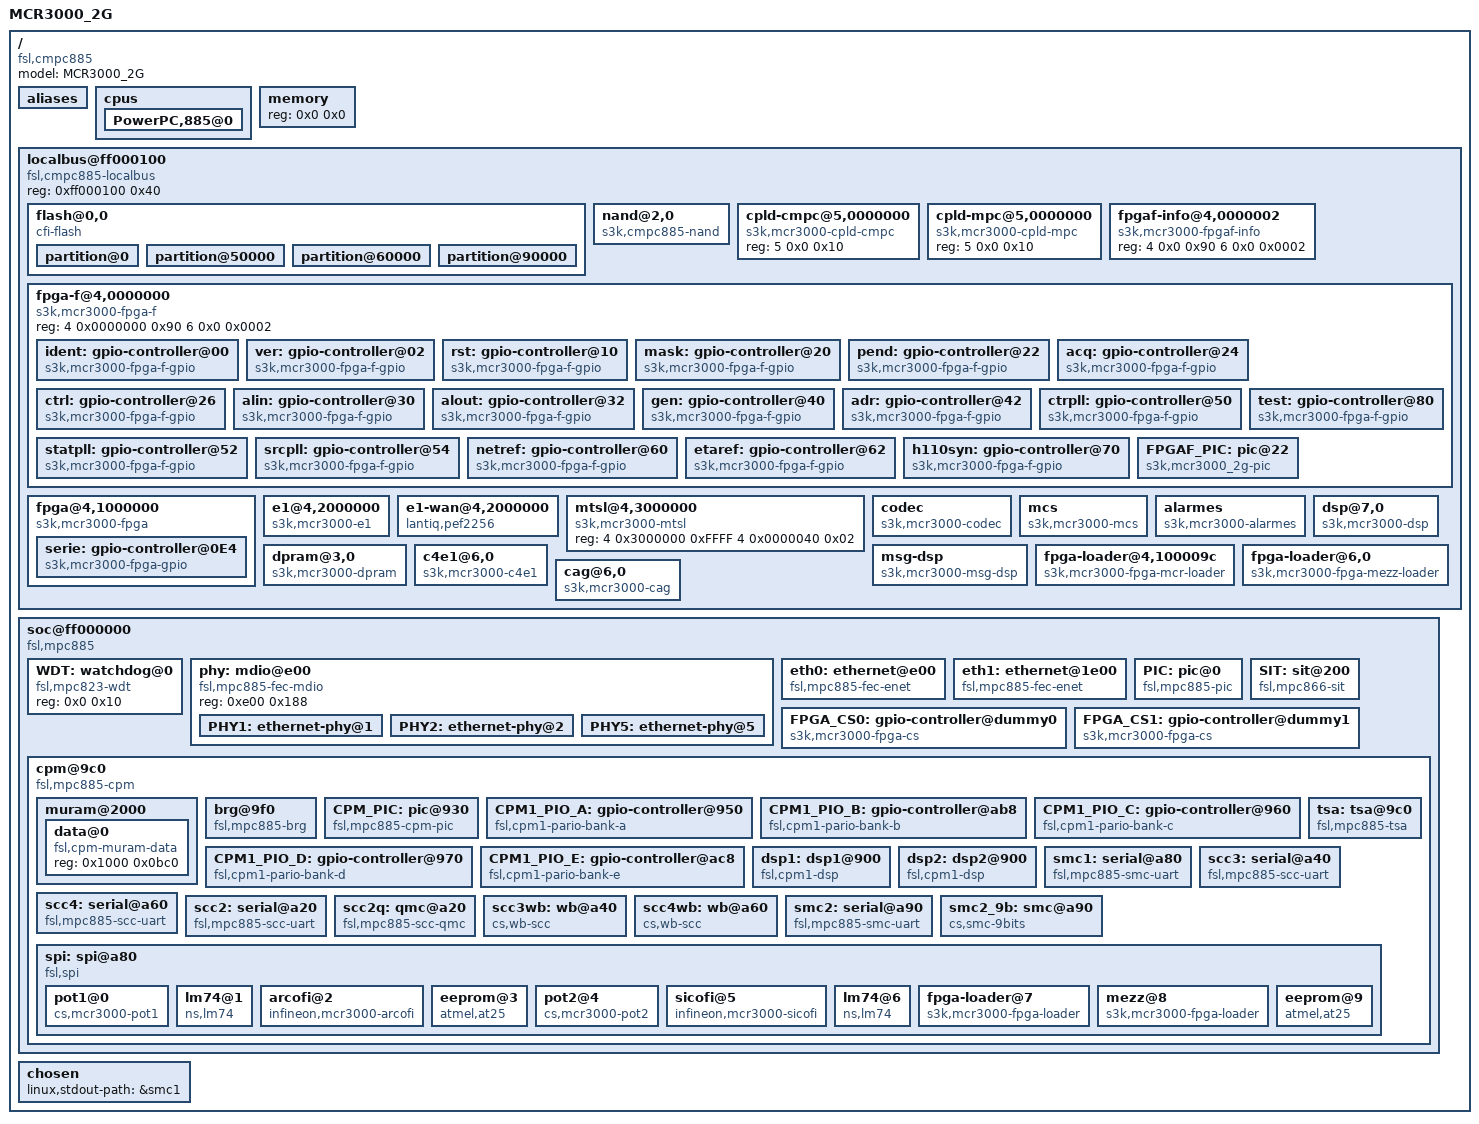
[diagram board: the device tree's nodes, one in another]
/*
 * MCR3000_2G Device Tree Source
 *
 * Copyright 2010 CSSI, Inc
 */

/dts-v1/;

/ {
	model = "MCR3000_2G";
	compatible = "fsl,cmpc885", "fsl,mod885", "fsl,base";
	#address-cells = <1>;
	#size-cells = <1>;

	aliases {
		ethernet0 = &eth0;
		ethernet1 = &eth1;
		mdio = &phy;
		serial0 = &smc1;
	};

	cpus {
		#address-cells = <1>;
		#size-cells = <0>;

		PowerPC,885@0 {
			device_type = "cpu";
			reg = <0x0>;
			d-cache-line-size = <16>;	// 16 bytes
			i-cache-line-size = <16>;	// 16 bytes
			d-cache-size = <8192>;
			i-cache-size = <8192>;
			timebase-frequency = <0>;
			bus-frequency = <0>;
			clock-frequency = <0>;
			interrupts = <15 2>;		// decrementer interrupt
			interrupt-parent = <&PIC>;
		};
	};

	memory {
		device_type = "memory";
		reg = <0x0 0x0>;			// defined by U-BOOT
	};

	localbus@ff000100 {
		compatible = "fsl,cmpc885-localbus", "fsl,pq1-localbus";
		#address-cells = <2>;
		#size-cells = <1>;
		reg = <0xff000100 0x40>;		// ORx and BRx register

		ranges = <0 0x0 0x40000000 0x00400000 // Boot Flash
			  1 0x0 0x00000000 0x08000000 // SDRAM
			  2 0x0 0xc0000000 0x00008000 // Nand Flash
			  3 0x0 0xe0000000 0x00010000 // DPRAM
			  4 0x0 0xd0000000 0x10000000 // Periphs
			  5 0x0 0xc8000000 0x00008000 // CPLD
			  6 0x0 0x80000000 0x00008000 // mezzanine
			  7 0x0 0xf0000000 0x00008000>; // DSP

		flash@0,0 {
			#address-cells = <1>;
			#size-cells = <1>;
			compatible = "cfi-flash";
			reg = <0x0 0x00000000 0x400000>;
			bank-width = <2>;
			device-width = <2>;
			partition@0 {
				label = "boot";
				reg = <0x0 0x50000>;
			};
			partition@50000 {
				label = "env";
				reg = <0x50000 0x10000>;
			};
			partition@60000 {
				label = "blob";
				reg = <0x60000 0x30000>;
			};
			partition@90000 {
				label = "kernel";
				reg = <0x90000 0x370000>;
			};
		};

		nand@2,0 {
			compatible = "s3k,cmpc885-nand";
			reg = <2 0x0 0x01>;
			#address-cells = <1>;
			#size-cells = <1>;
			gpios = <&CPM1_PIO_D 12 1 	// CLE
				 &CPM1_PIO_D 13 1	// ALE
				 &CPM1_PIO_D 15 1>;	// NCE
		};

		cpld-cmpc@5,0000000 { // Driver KNL
			#address-cells = <1>;
			#size-cells = <1>;
			compatible = "s3k,mcr3000-cpld-cmpc";
			reg = <5 0x0 0x10>;
		};
		
		cpld-mpc@5,0000000 { // Driver LDB (deviendra obsolete)
			#address-cells = <1>;
			#size-cells = <1>;
			compatible = "s3k,mcr3000-cpld-mpc";
			reg = <5 0x0 0x10>;
		};
		
		fpgaf-info@4,0000002 { // Driver KNL
			#address-cells = <1>;
			#size-cells = <1>;
			compatible = "s3k,mcr3000-fpgaf-info";
			reg = <4 0x0 0x90 6 0x0 0x0002>;	// Mappage registres FPGAF ; Ident carte Mezzanine
		};

		fpga-f@4,0000000 { // Driver LDB (deviendra peut etre obsolete)
			#address-cells = <1>;
			#size-cells = <1>;
			compatible = "s3k,mcr3000-fpga-f";
			reg = <4 0x0000000 0x90 6 0x0 0x0002>;
			ranges = <0 4 0x0000000 0x90>;
			ident: gpio-controller@00 {
				#gpio-cells = <2>;
				compatible = "s3k,mcr3000-fpga-f-gpio";
				reg = <0x00 2>;
				gpio-controller;
			};
			ver: gpio-controller@02 {
				#gpio-cells = <2>;
				compatible = "s3k,mcr3000-fpga-f-gpio";
				reg = <0x02 2>;
				gpio-controller;
			};
			rst: gpio-controller@10 {
				#gpio-cells = <2>;
				compatible = "s3k,mcr3000-fpga-f-gpio";
				reg = <0x10 2>;
				gpio-controller;
			};
			mask: gpio-controller@20 {
				#gpio-cells = <2>;
				compatible = "s3k,mcr3000-fpga-f-gpio";
				reg = <0x20 2>;
				gpio-controller;
			};
			pend: gpio-controller@22 {
				#gpio-cells = <2>;
				compatible = "s3k,mcr3000-fpga-f-gpio";
				reg = <0x22 2>;
				gpio-controller;
			};
			acq: gpio-controller@24 {
				#gpio-cells = <2>;
				compatible = "s3k,mcr3000-fpga-f-gpio";
				reg = <0x24 2>;
				gpio-controller;
			};
			ctrl: gpio-controller@26 {
				#gpio-cells = <2>;
				compatible = "s3k,mcr3000-fpga-f-gpio";
				reg = <0x26 2>;
				gpio-controller;
			};
			alin: gpio-controller@30 {
				#gpio-cells = <2>;
				compatible = "s3k,mcr3000-fpga-f-gpio";
				reg = <0x30 2>;
				interrupts = <255 255 255 255 255 255 255 255 8 9 10 11 12 13 14 15>;
				interrupt-parent = <&FPGAF_PIC>;
				gpio-controller;
			};
			alout: gpio-controller@32 {
				#gpio-cells = <2>;
				compatible = "s3k,mcr3000-fpga-f-gpio";
				reg = <0x32 2>;
				gpio-controller;
			};
			gen: gpio-controller@40 {
				#gpio-cells = <2>;
				compatible = "s3k,mcr3000-fpga-f-gpio";
				reg = <0x40 2>;
				gpio-controller;
			};
			adr: gpio-controller@42 {
				#gpio-cells = <2>;
				compatible = "s3k,mcr3000-fpga-f-gpio";
				reg = <0x42 2>;
				gpio-controller;
			};
			ctrpll: gpio-controller@50 {
				#gpio-cells = <2>;
				compatible = "s3k,mcr3000-fpga-f-gpio";
				reg = <0x50 2>;
				gpio-controller;
			};
			statpll: gpio-controller@52 {
				#gpio-cells = <2>;
				compatible = "s3k,mcr3000-fpga-f-gpio";
				reg = <0x52 2>;
				gpio-controller;
			};
			srcpll: gpio-controller@54 {
				#gpio-cells = <2>;
				compatible = "s3k,mcr3000-fpga-f-gpio";
				reg = <0x54 2>;
				gpio-controller;
			};
			netref: gpio-controller@60 {
				#gpio-cells = <2>;
				compatible = "s3k,mcr3000-fpga-f-gpio";
				reg = <0x60 2>;
				gpio-controller;
			};
			etaref: gpio-controller@62 {
				#gpio-cells = <2>;
				compatible = "s3k,mcr3000-fpga-f-gpio";
				reg = <0x62 2>;
				interrupts = <255 255 255 255 255 255 255 255 255 255 2 4 3 5 6 7>;
				interrupt-parent = <&FPGAF_PIC>;
				gpio-controller;
			};
			h110syn: gpio-controller@70 {
				#gpio-cells = <2>;
				compatible = "s3k,mcr3000-fpga-f-gpio";
				reg = <0x70 2>;
				gpio-controller;
			};
			test: gpio-controller@80 {
				#gpio-cells = <2>;
				compatible = "s3k,mcr3000-fpga-f-gpio";
				reg = <0x80 2>;
				gpio-controller;
			};
			FPGAF_PIC: pic@22 {
				interrupt-controller;
				#address-cells = <0>;
				#interrupt-cells = <1>;
				interrupts = <14 1>;
				interrupt-parent = <&PIC>;
				reg = <0x0 0x90>;	// Mappage registres FPGAF
				compatible = "s3k,mcr3000_2g-pic";
			};
		};
		
		fpga@4,1000000 {
			#address-cells = <1>;
			#size-cells = <1>;
			compatible = "s3k,mcr3000-fpga";
			reg = <4 0x1000000 0x0200 6 0x0 0x0002 4 0x60 0x02 4 0x10000E8 0x02>;
			/* registres FPGA - Registre ident MEZZ (1G) - Registre NetRef FPGAF - Registre BRG5 FPGA */
			ranges = <0 4 0x1000000 0x0200>;
			liens = "SCC3", "SCC4", "SCC2", "SMC2";
//			interrupts = <0>;
//			interrupt-parent = <&FPGA_PIC>;
			interrupts = <6 1>;
			interrupt-parent = <&PIC>;
			serie: gpio-controller@0E4 {
				#gpio-cells = <2>;
				compatible = "s3k,mcr3000-fpga-gpio";
				reg = <0x0E4 2>;
				gpio-controller;
			};
//			FPGA_PIC: pic@1000000 {
//				interrupt-controller;
//				#address-cells = <0>;
//				#interrupt-cells = <1>;
//				interrupts = <6 1>;
//				interrupt-parent = <&PIC>;
//				reg = <0x0 0x0200>;	/* Mappage registres FPGA */
//				compatible = "s3k,mcr3000-fpga-pic";
//			};
		};
		
//		uart-fpga@4,1000000 {
//			#address-cells = <1>;
//			#size-cells = <1>;
//			compatible = "ns16550a";
//			/* adresse uart 16550a et taille utile */
//			reg = <4 0x1000100 0x100>;
//			reg-shift = <1>;
//			fifo-size = <32>;
//			clock = "fpga";
//			interrupts = <1>;
//			interrupt-parent = <&FPGA_PIC>;
//		};

		e1@4,2000000 {
			#address-cells = <1>;
			#size-cells = <1>;
			compatible = "s3k,mcr3000-e1";
			reg = <4 0x2000000 0xFF>;
			interrupts = <8 1>;
			interrupt-parent = <&PIC>;
		};
		
		e1-wan@4,2000000 {
			#address-cells = <1>;
			#size-cells = <1>;
			compatible = "lantiq,pef2256";
			reg = <4 0x2000000 0xFF>;
			interrupts = <8 1>;
			interrupt-parent = <&PIC>;
		};
		
		mtsl@4,3000000 {
			#address-cells = <1>;
			#size-cells = <1>;
			compatible = "s3k,mcr3000-mtsl";
			reg = <4 0x3000000 0xFFFF 4 0x0000040 0x02>;
		};

		codec {
			compatible = "s3k,mcr3000-codec";
		};

		mcs {
			compatible = "s3k,mcr3000-mcs";
		};

		alarmes {
			compatible = "s3k,mcr3000-alarmes";
			gpios = <&alin 13 1 	// ACQ_ALRM
				&alout 15 1	// ALRM_MAJ
				&alout 14 1>;	// ALRM_MIN
		};
		
		dpram@3,0 {
			#address-cells = <1>;
			#size-cells = <1>;
			compatible = "s3k,mcr3000-dpram";
			reg = <3 0x0 0x10000>;
			interrupts = <4 1>;
			interrupt-parent = <&PIC>;
		};

		dsp@7,0 {
			#address-cells = <1>;
			#size-cells = <1>;
			compatible = "s3k,mcr3000-dsp";
			reg = <7 0x0 0x0008>;
			interrupts = <0 1>;
			interrupt-parent = <&FPGAF_PIC>;
		};

		msg-dsp {
			#address-cells = <1>;
			#size-cells = <1>;
			compatible = "s3k,mcr3000-msg-dsp";
			reg = <3 0x0 0x300>;
			interrupts = <0 1>;
			interrupt-parent = <&FPGAF_PIC>;
		};

		fpga-loader@4,100009c {
			#address-cells = <1>;
			#size-cells = <1>;
			compatible = "s3k,mcr3000-fpga-mcr-loader";
			reg = <4 0x100009c 2>;			// Version FPGA
			gpios = <&FPGA_CS0 1 1			// INITFPGA
				 &CPM1_PIO_E 23 1		// DONEFPGA
				 &rst 13 1 >;			// RST_FPGA
		};
		c4e1@6,0 {
			#address-cells = <1>;
			#size-cells = <1>;
			compatible = "s3k,mcr3000-c4e1";
			reg = <6 0x100 0x00FF 6 0x200 0x00FF 6 0x300 0x00FF 6 0x400 0x00FF 6 0x500 0x00FF>;
			interrupts = <12 1>;
			interrupt-parent = <&PIC>;
		};

		fpga-loader@6,0 {
			#address-cells = <1>;
			#size-cells = <1>;
			compatible = "s3k,mcr3000-fpga-mezz-loader";
			reg = <6 0x500 2>; 		// Version FPGA Mezz
			gpios = <&FPGA_CS1 1 1		// INIT Mezz
				&CPM1_PIO_B 17 1	// DONE Mezz
				&rst 9 1 >;		// RST Mezz
		};

		cag@6,0 {
			#address-cells = <1>;
			#size-cells = <1>;
			compatible = "s3k,mcr3000-cag";
			reg = <6 0x0 0x0020>;
			interrupts = <12 1>;
			interrupt-parent = <&PIC>;
		};
	};

	soc@ff000000 {
		compatible = "fsl,mpc885", "fsl,pq1-soc";
		#address-cells = <1>;
		#size-cells = <1>;
		device_type = "soc";
		ranges = <0x0 0xff000000 0x28000>;
		bus-frequency = <0>;
		clock-frequency = <0>;

		WDT: watchdog@0 {
			compatible = "fsl,mpc823-wdt";
			reg = <0x0 0x10>;
		};

		phy: mdio@e00 {
			compatible = "fsl,mpc885-fec-mdio", "fsl,pq1-fec-mdio";
			reg = <0xe00 0x188>;
			#address-cells = <1>;
			#size-cells = <0>;

			PHY1: ethernet-phy@1 {
				interrupts = <2 1>;
				interrupt-parent = <&PIC>;
				reg = <0x1>;
				device_type = "ethernet-phy";
			};

			PHY2: ethernet-phy@2 {
				interrupts = <2 1>;
				interrupt-parent = <&PIC>;
				reg = <0x2>;
				device_type = "ethernet-phy";
			};

			PHY5: ethernet-phy@5 {
				interrupts = <2 1>;
				interrupt-parent = <&PIC>;
				reg = <0x5>;
				device_type = "ethernet-phy";
			};
		};

		eth0: ethernet@e00 {
			device_type = "network";
			compatible = "fsl,mpc885-fec-enet", "fsl,pq1-fec-enet";
			reg = <0xe00 0x188>;
			local-mac-address = [ 00 00 00 00 00 00 ];
			interrupts = <5 1>;
			interrupt-parent = <&PIC>;
			phy-handle = <&PHY1 &PHY5>;
			linux,network-index = <0>;
			use-PHY5;
			gpios = <&rst 15 1>;		// Reset Eth1
			PHY-disable = "isolate";
		};

		eth1: ethernet@1e00 {
			device_type = "network";
			compatible = "fsl,mpc885-fec-enet", "fsl,pq1-fec-enet";
			reg = <0x1e00 0x188>;
			local-mac-address = [ 00 00 00 00 00 00 ];
			interrupts = <7 1>;
			interrupt-parent = <&PIC>;
			phy-handle = <&PHY2>;
			linux,network-index = <1>;
		};

		PIC: pic@0 {
			interrupt-controller;
			#interrupt-cells = <2>;
			reg = <0x0 0x24>;
			compatible = "fsl,mpc885-pic", "fsl,pq1-pic";
		};

		SIT: sit@200 {
			compatible = "fsl,mpc866-sit", "fsl,pq1-sit";
			reg = <0x200 0x80>;
			interrupts = <11 1>;
			interrupt-parent = <&PIC>;
		};

		FPGA_CS0: gpio-controller@dummy0 {
			#gpio-cells = <2>;
			compatible = "s3k,mcr3000-fpga-cs";
			gpio-controller;
			reg = <0x0 0x1>;	// necessaire mais non utilise
			gpios = <&CPM1_PIO_E 18 1	// PROGFPGA
				 &CPM1_PIO_D 6 1>;	// INITFPGA
		};
		FPGA_CS1: gpio-controller@dummy1 {
			#gpio-cells = <2>;
			compatible = "s3k,mcr3000-fpga-cs";
			gpio-controller;
			reg = <0x1 0x1>; /* necessaire mais non utilise */
			gpios = <&CPM1_PIO_B 16 1	// PROG
				 &CPM1_PIO_B 22 1>;	// INIT
		};

		cpm@9c0 {
			#address-cells = <1>;
			#size-cells = <1>;
			compatible = "fsl,mpc885-cpm", "fsl,cpm1";
			ranges;
			reg = <0x9c0 0x40>;
			brg-frequency = <0>;
			interrupts = <0>;	// cpm error interrupt
			interrupt-parent = <&CPM_PIC>;

			muram@2000 {
				#address-cells = <1>;
				#size-cells = <1>;
				ranges = <0x0 0x2000 0x2000>;

				/* conserver les 4 premiers Kbytes pour QMC */
				data@0 {
					compatible = "fsl,cpm-muram-data";
					reg = <0x1000 0x0bc0>;
				};
			};

			brg@9f0 {
				compatible = "fsl,mpc885-brg", "fsl,cpm1-brg", "fsl,cpm-brg";
				reg = <0x9f0 0x10>;
				clock-frequency = <0>;
			};

			CPM_PIC: pic@930 {
				interrupt-controller;
				#address-cells = <0>;
				#interrupt-cells = <1>;
				interrupts = <3 2 0 2>;
				interrupt-parent = <&PIC>;
				reg = <0x930 0x20>;
				compatible = "fsl,mpc885-cpm-pic", "fsl,cpm1-pic";
			};

			CPM1_PIO_A: gpio-controller@950 {
				#gpio-cells = <2>;
				compatible = "fsl,cpm1-pario-bank-a";
				reg = <0x950 0x10>;
				gpio-controller;
			};
		
			CPM1_PIO_B: gpio-controller@ab8 {
				#gpio-cells = <2>;
				compatible = "fsl,cpm1-pario-bank-b";
				reg = <0xab8 0x10>;
				gpio-controller;
			};
		
			CPM1_PIO_C: gpio-controller@960 {
				#gpio-cells = <2>;
				compatible = "fsl,cpm1-pario-bank-c";
				reg = <0x960 0x10>;
				interrupts = <0 0 0 0 1 2 6 9 10 11 14 15 23 24 26 31>;
				interrupt-parent = <&CPM_PIC>;
				gpio-controller;
			};
		
			CPM1_PIO_D: gpio-controller@970 {
				#gpio-cells = <2>;
				compatible = "fsl,cpm1-pario-bank-d";
				reg = <0x970 0x10>;
				gpio-controller;
			};
		
			CPM1_PIO_E: gpio-controller@ac8 {
				#gpio-cells = <2>;
				compatible = "fsl,cpm1-pario-bank-e";
				reg = <0xac8 0x18>;
				gpio-controller;
			};
			
			dsp1: dsp1@900 {
				device_type = "dsp";
				compatible = "fsl,cpm1-dsp";
				reg = <0x900 0x30 0x3ec0 0x40>;
				interrupts = <22>;
				interrupt-parent = <&CPM_PIC>;
				fsl,cpm-dsp = <1>;
				fsl,cpm-command = <0x90>;
			};

			dsp2: dsp2@900 {
				device_type = "dsp";
				compatible = "fsl,cpm1-dsp";
				reg = <0x900 0x30 0x3fc0 0x40>;
				interrupts = <22>;
				interrupt-parent = <&CPM_PIC>;
				fsl,cpm-dsp = <2>;
				fsl,cpm-command = <0xd0>;
			};

			tsa: tsa@9c0 {
				compatible = "fsl,mpc885-tsa", "fsl,cpm1-tsa";
				reg = <0x9c0 0x440 0x930 0x20>;
				/* parametres possible : none, SCC2 */
				scc_qmc_mcr = "SCC2";
				/* parametre enregistrement : TS sup 0 a 16 */
				ts_enreg = <16>;
			};

			smc1: serial@a80 {
				device_type = "serial";
				compatible = "fsl,mpc885-smc-uart", "fsl,cpm1-smc-uart";
				reg = <0xa80 0x10 0x3e80 0x40>;
				interrupts = <4>;
				interrupt-parent = <&CPM_PIC>;
				fsl,cpm-brg = <4>;
				fsl,cpm-command = <0x90>;
			};

			scc3: serial@a40 {	/* SCC3 = LS1 */
				device_type = "serial";
				compatible = "fsl,mpc885-scc-uart", "fsl,cpm1-scc-uart";
				reg = <0xa40 0x20 0x3e00 0x80>;
				interrupts = <28>;
				interrupt-parent = <&CPM_PIC>;
				fsl,cpm-brg = <2>;
				fsl,cpm-command = <0x80>;
				gpios = <&CPM1_PIO_C 5 1	/* CTS3 */
				         &CPM1_PIO_D 7 1>;	/* RTS3 */
			};

			scc4: serial@a60 {	/* SCC4 = LS2 */
				device_type = "serial";
				compatible = "fsl,mpc885-scc-uart", "fsl,cpm1-scc-uart";
				reg = <0xa60 0x20 0x3f00 0x80>;
				interrupts = <27>;
				interrupt-parent = <&CPM_PIC>;
				fsl,cpm-brg = <3>;
				fsl,cpm-command = <0xc0>;
				gpios = <&serie 9 1		/* CTS4 */
				         &serie 11 1>;		/* RTS4 */
			};

			scc2: serial@a20 {	/* SCC2 = QMC ou LS3 */
				device_type = "serial";
				compatible = "fsl,mpc885-scc-uart", "fsl,cpm1-scc-uart";
				reg = <0xa20 0x20 0x3d00 0x80>;
				interrupts = <29>;
				interrupt-parent = <&CPM_PIC>;
				fsl,cpm-brg = <1>;
				fsl,cpm-command = <0x40>;
				gpios = <&CPM1_PIO_C 9 1	/* CTS2 */
				         &CPM1_PIO_B 18 1>;	/* RTS2 */
			};

			scc2q: qmc@a20 {
				device_type = "qmc";
				qmc_name = "scc2";
				compatible = "fsl,mpc885-scc-qmc", "fsl,cpm1-scc-qmc";
				reg = <0xa20 0x20 0x3d00 0xb0 0x2000 0x1000>;
				interrupts = <29>;
				interrupt-parent = <&CPM_PIC>;
				fsl,cpm-command = <0x40>;
			};

			scc3wb: wb@a40 {
				device_type = "wb_scc";
				wb_name = "ls1";
				scc_name = "scc3";
				compatible = "cs,wb-scc";
				reg = <0xa40 0x20 0x3e00 0x80>;
				interrupts = <28 2>;		/* scc, cts */
				interrupt-parent = <&CPM_PIC>;
				fsl,cpm-brg = <2>;
				fsl,cpm-command = <0x80>;
				gpios = <&CPM1_PIO_C 5 1	/* CTS3 */
				         &CPM1_PIO_D 7 1>;	/* RTS3 */
			};

			scc4wb: wb@a60 {
				device_type = "wb_scc";
				wb_name = "ls2";
				scc_name = "scc4";
				compatible = "cs,wb-scc";
				reg = <0xa60 0x20 0x3f00 0x80>;
				interrupts = <27>;
//				interrupts = <27 xx>;		/* scc, cts */
				interrupt-parent = <&CPM_PIC>;
				fsl,cpm-brg = <3>;
				fsl,cpm-command = <0xc0>;
				gpios = <&serie 9 1		/* CTS4 */
				         &serie 11 1>;		/* RTS4 */
			};

			smc2: serial@a90 {
				device_type = "serial";
				compatible = "fsl,mpc885-smc-uart", "fsl,cpm1-smc-uart";
				reg = <0xa90 0x10 0x3f80 0x40>;
				interrupts = <3>;
				interrupt-parent = <&CPM_PIC>;
//				fsl,cpm-brg = <3>; /* normalement mettre une clock venant du FPGA */
				clock = "fpga";
				fsl,cpm-command = <0xd0>;
				gpios = <&serie 8 1		/* CTS5 */
				         &serie 10 1>;		/* RTS5 */
			};

			smc2_9b: smc@a90 {
				device_type = "smc_9bits";
				compatible = "cs,smc-9bits";
				reg = <0xa90 0x10 0x3f80 0x40 0x9c0 0x440>;
				interrupts = <3>;
				interrupt-parent = <&CPM_PIC>;
				clock = "fpga";
				fsl,cpm-command = <0xd0>;
				gpios = <&serie 8 1		/* CTS5 */
				         &serie 10 1>;		/* RTS5 */
			};

			spi: spi@a80 {
				#address-cells = <1>;
				#size-cells = <0>;
				cell-index = <0>;
				compatible = "fsl,spi", "fsl,cpm1-spi";
				reg = <0xa80 0x30 0x3d80 0x30>;
				interrupts = <5>;
				interrupt-parent = <&CPM_PIC>;
				mode = "cpu";
				gpios = <&CPM1_PIO_C 13 1	/* POT1 */
					 &CPM1_PIO_B 23 1	/* TEMP MCR */
					 &CPM1_PIO_C 8 1	/* ARCOFI */
					 &CPM1_PIO_C 12 1	/* EEPROM MCR3000 2G*/
					 &CPM1_PIO_C 14 1	/* POT2 */
					 &CPM1_PIO_C 4 1	/* SICOFI */
					 &CPM1_PIO_B 14 1	/* TEMP MPC885 */
					 &FPGA_CS0 0 1		/* FPGA Radio */
					 &FPGA_CS1 0 1		/* FPGA Mezz */
					 &CPM1_PIO_B 21 1>;	/* EEPROM CMPC885 */
				pot1@0 {
					compatible = "cs,mcr3000-pot1";
					spi-max-frequency = <1000000>;
					reg = <0>;
					spi-cs-high;
				};
				lm74@1 {
					compatible = "ns,lm74";
					spi-max-frequency = <1000000>;
					reg = <1>;
					spi-cs-high;
				};
				arcofi@2 {
					compatible = "infineon,mcr3000-arcofi";
					spi-max-frequency = <1000000>;
					reg = <2>;
					spi-cs-high;
					spi-cpha;
					spi-troll;
				};
				eeprom@3 {
					compatible = "atmel,at25", "cs,eeprom";
					spi-max-frequency = <1000000>;
					reg = <3>;
					spi-cs-high;
					at25,byte-len = <1024>;
					at25,addr-mode = <2>;
					at25,page-size = <32>;
				};
				pot2@4 {
					compatible = "cs,mcr3000-pot2";
					spi-max-frequency = <1000000>;
					reg = <4>;
					spi-cs-high;
				};
				sicofi@5 {
					compatible = "infineon,mcr3000-sicofi";
					spi-max-frequency = <1000000>;
					reg = <5>;
					spi-cs-high;
					spi-cpha;
					spi-troll;
				};
				lm74@6 {
					compatible = "ns,lm74";
					spi-max-frequency = <1000000>;
					reg = <6>;
					spi-cs-high;
				};
				fpga-loader@7 {
					compatible = "s3k,mcr3000-fpga-loader";
					spi-max-frequency = <10000000>;
					reg = <7>;
					spi-cs-high;
					loader = "mcr";
					spi-bits = <16>;
				};
				mezz@8 {
					compatible = "s3k,mcr3000-fpga-loader";
					spi-max-frequency = <10000000>;
					reg = <8>;
					spi-cs-high;
					loader = "mezz";
					spi-bits = <16>;
				};
				eeprom@9 {
					compatible = "atmel,at25", "cs,eeprom";
					spi-max-frequency = <1000000>;
					reg = <9>;
					spi-cs-high;
					at25,byte-len = <1024>;
					at25,addr-mode = <2>;
					at25,page-size = <32>;
				};
				
			};
		};
			
/*		crypto@20000 {
			compatible = "fsl,sec2.0";
			reg = <0x20000 0x8000>;
			interrupts = <1 1>;
			interrupt-parent = <&PIC>;
			fsl,num-channels = <1>;
			fsl,channel-fifo-len = <24>;
			fsl,exec-units-mask = <0x4c>;
			fsl,descriptor-types-mask = <0x301f>;
		};
*/	};

	chosen {
		linux,stdout-path = &smc1;
	};
};
